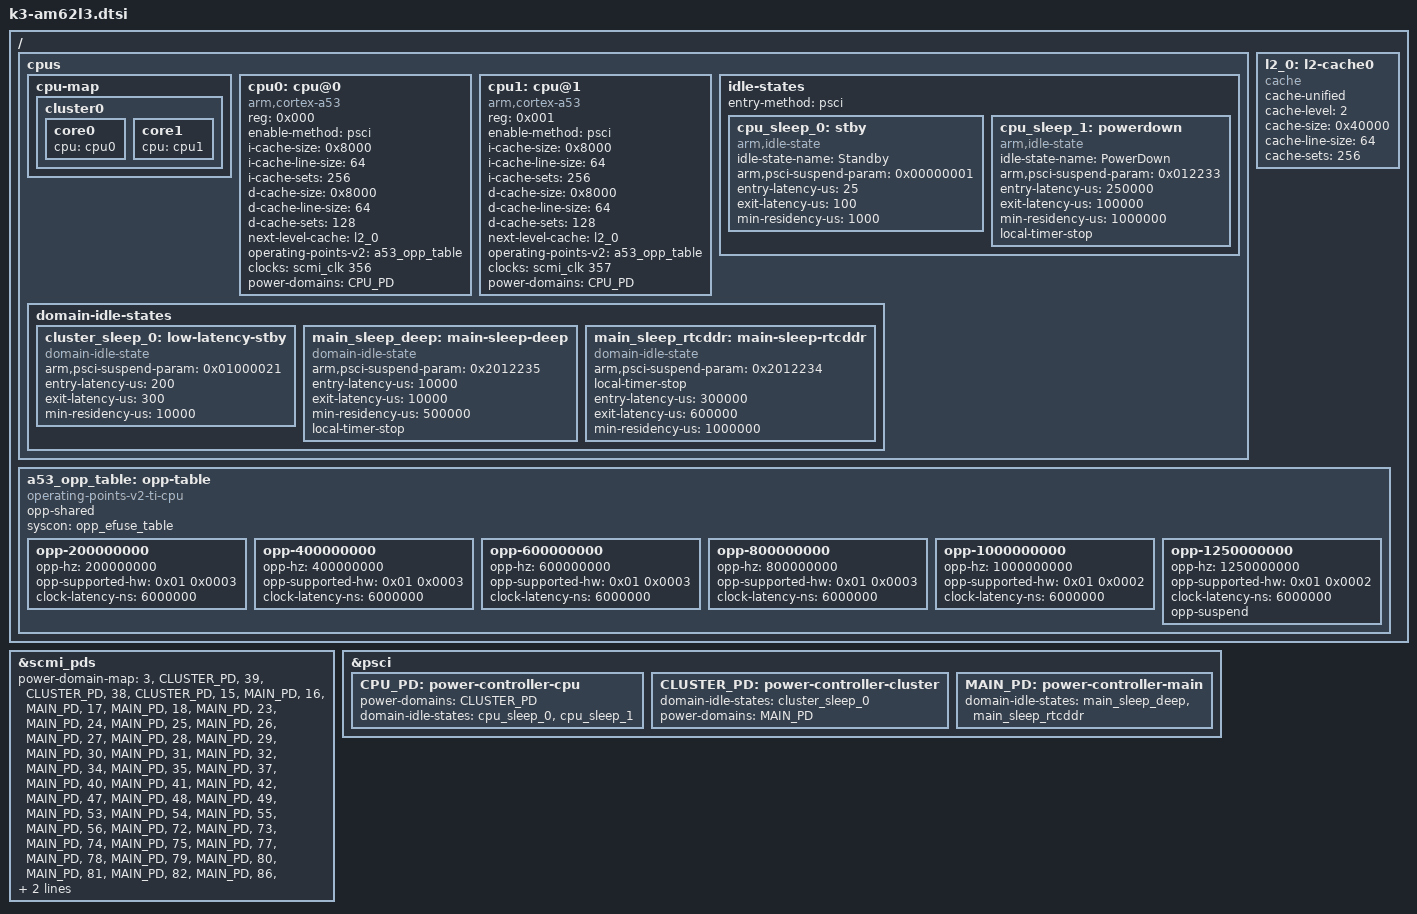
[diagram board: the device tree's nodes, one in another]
// SPDX-License-Identifier: GPL-2.0-only or MIT
/*
 * Device Tree file for the AM62L3 SoC family (Dual Core A53)
 * Copyright (C) 2025 Texas Instruments Incorporated - https://www.ti.com/
 *
 * Technical Reference Manual: https://www.ti.com/lit/pdf/sprujb4
 */

/dts-v1/;

#include "k3-am62l.dtsi"

/ {
	cpus {
		#address-cells = <1>;
		#size-cells = <0>;

		cpu-map {
			cluster0: cluster0 {
				core0 {
					cpu = <&cpu0>;
				};

				core1 {
					cpu = <&cpu1>;
				};
			};
		};

		cpu0: cpu@0 {
			compatible = "arm,cortex-a53";
			reg = <0x000>;
			device_type = "cpu";
			enable-method = "psci";
			i-cache-size = <0x8000>;
			i-cache-line-size = <64>;
			i-cache-sets = <256>;
			d-cache-size = <0x8000>;
			d-cache-line-size = <64>;
			d-cache-sets = <128>;
			next-level-cache = <&l2_0>;
			operating-points-v2 = <&a53_opp_table>;
			clocks = <&scmi_clk 356>;
			power-domains = <&CPU_PD>;
			power-domain-names = "psci";
		};

		cpu1: cpu@1 {
			compatible = "arm,cortex-a53";
			reg = <0x001>;
			device_type = "cpu";
			enable-method = "psci";
			i-cache-size = <0x8000>;
			i-cache-line-size = <64>;
			i-cache-sets = <256>;
			d-cache-size = <0x8000>;
			d-cache-line-size = <64>;
			d-cache-sets = <128>;
			next-level-cache = <&l2_0>;
			operating-points-v2 = <&a53_opp_table>;
			clocks = <&scmi_clk 357>;
			power-domains = <&CPU_PD>;
			power-domain-names = "psci";
		};

		idle-states {
			entry-method = "psci";

			cpu_sleep_0: stby {
				compatible = "arm,idle-state";
				idle-state-name = "Standby";
				arm,psci-suspend-param = <0x00000001>;
				entry-latency-us = <25>;
				exit-latency-us = <100>;
				min-residency-us = <1000>;
			};
			cpu_sleep_1: powerdown {
				compatible = "arm,idle-state";
				idle-state-name = "PowerDown";
				arm,psci-suspend-param = <0x012233>;
				entry-latency-us = <250000>;
				exit-latency-us = <100000>;
				min-residency-us = <1000000>;
				local-timer-stop;
			};
		};

		domain-idle-states {
			cluster_sleep_0: low-latency-stby {
				compatible = "domain-idle-state";
				arm,psci-suspend-param = <0x01000021>;
				entry-latency-us = <200>;
				exit-latency-us = <300>;
				min-residency-us = <10000>;
			};

			main_sleep_deep: main-sleep-deep {
				compatible = "domain-idle-state";
				arm,psci-suspend-param = <0x2012235>;
				entry-latency-us = <10000>;
				exit-latency-us = <10000>;
				min-residency-us = <500000>;
				local-timer-stop;
			};

			main_sleep_rtcddr: main-sleep-rtcddr {
				compatible = "domain-idle-state";
				arm,psci-suspend-param = <0x2012234>;
				local-timer-stop;
				entry-latency-us = <300000>;
				exit-latency-us = <600000>;
				min-residency-us = <1000000>;
			};
		};
	};

	l2_0: l2-cache0 {
		compatible = "cache";
		cache-unified;
		cache-level = <2>;
		cache-size = <0x40000>;
		cache-line-size = <64>;
		cache-sets = <256>;
	};

	a53_opp_table: opp-table {
		compatible = "operating-points-v2-ti-cpu";
		opp-shared;
		syscon = <&opp_efuse_table>;

		opp-200000000 {
			opp-hz = /bits/ 64 <200000000>;
			opp-supported-hw = <0x01 0x0003>;
			clock-latency-ns = <6000000>;
		};

		opp-400000000 {
			opp-hz = /bits/ 64 <400000000>;
			opp-supported-hw = <0x01 0x0003>;
			clock-latency-ns = <6000000>;
		};

		opp-600000000 {
			opp-hz = /bits/ 64 <600000000>;
			opp-supported-hw = <0x01 0x0003>;
			clock-latency-ns = <6000000>;
		};

		opp-800000000 {
			opp-hz = /bits/ 64 <800000000>;
			opp-supported-hw = <0x01 0x0003>;
			clock-latency-ns = <6000000>;
		};

		opp-1000000000 {
			opp-hz = /bits/ 64 <1000000000>;
			opp-supported-hw = <0x01 0x0002>;
			clock-latency-ns = <6000000>;
		};

		opp-1250000000 {
			opp-hz = /bits/ 64 <1250000000>;
			opp-supported-hw = <0x01 0x0002>;
			clock-latency-ns = <6000000>;
			opp-suspend;
		};
	};
};
/*
 * HACK : Adding DSS driver under the Cluster PD
 * The standby state puts DDR in Auto Self Refresh, however due to a bug in DDR Auto self refresh
 * when the display is active, DSS driver faces Plane Underflow and SYNC_LOST errors.
 * This is a workaround to prevent entry into standby when the display is active.
 */
&scmi_pds {
	power-domain-map = <3 &CLUSTER_PD>, /* CPSW3G */
			   <39 &CLUSTER_PD>, /* DSS0 */
			   <38 &CLUSTER_PD>, /* DSS_DSI0 */
			   <15 &MAIN_PD>, /* TIMER0 */
			   <16 &MAIN_PD>, /* TIMER1 */
			   <17 &MAIN_PD>, /* TIMER2 */
			   <18 &MAIN_PD>, /* TIMER3 */
			   <23 &MAIN_PD>, /* ECAP0 */
			   <24 &MAIN_PD>, /* ECAP1 */
			   <25 &MAIN_PD>, /* ECAP2/ELM0 */
			   <26 &MAIN_PD>, /* SDHCI1 */
			   <27 &MAIN_PD>, /* SDHCI2 */
			   <28 &MAIN_PD>, /* SDHCI0 */
			   <29 &MAIN_PD>, /* EQEP0 */
			   <30 &MAIN_PD>, /* EQEP1 */
			   <31 &MAIN_PD>, /* EQEP2 */
			   <32 &MAIN_PD>, /* OSPI0 */
			   <34 &MAIN_PD>, /* GPIO0 */
			   <35 &MAIN_PD>, /* GPIO2 */
			   <37 &MAIN_PD>, /* GPMC0 */
			   <40 &MAIN_PD>, /* EPWM0 */
			   <41 &MAIN_PD>, /* EPWM1 */
			   <42 &MAIN_PD>, /* EPWM2 */
			   <47 &MAIN_PD>, /* MCAN0 */
			   <48 &MAIN_PD>, /* MCAN1 */
			   <49 &MAIN_PD>, /* MCAN2 */
			   <53 &MAIN_PD>, /* I2C0 */
			   <54 &MAIN_PD>, /* I2C1 */
			   <55 &MAIN_PD>, /* I2C2 */
			   <56 &MAIN_PD>, /* I2C3 */
			   <72 &MAIN_PD>, /* SPI0 */
			   <73 &MAIN_PD>, /* SPI1 */
			   <74 &MAIN_PD>, /* SPI2 */
			   <75 &MAIN_PD>, /* SPI3 */
			   <77 &MAIN_PD>, /* UART1 */
			   <78 &MAIN_PD>, /* UART2 */
			   <79 &MAIN_PD>, /* UART3 */
			   <80 &MAIN_PD>, /* UART4 */
			   <81 &MAIN_PD>, /* UART5 */
			   <82 &MAIN_PD>, /* UART6 */
			   <86 &MAIN_PD>, /* DPHY_TX0 */
			   <89 &MAIN_PD>, /* UART0 */
			   <95 &MAIN_PD>, /* USBSS0 */
			   <96 &MAIN_PD>; /* USBSS1 */
};

&psci {
	CPU_PD: power-controller-cpu {
		#power-domain-cells = <0>;
		power-domains = <&CLUSTER_PD>;
		domain-idle-states = <&cpu_sleep_0>, <&cpu_sleep_1>;
	};

	CLUSTER_PD: power-controller-cluster {
		#power-domain-cells = <0>;
		domain-idle-states = <&cluster_sleep_0>;
		power-domains = <&MAIN_PD>;
	};

	MAIN_PD: power-controller-main {
                #power-domain-cells = <0>;
                domain-idle-states = <&main_sleep_deep>, <&main_sleep_rtcddr>;
        };
};
